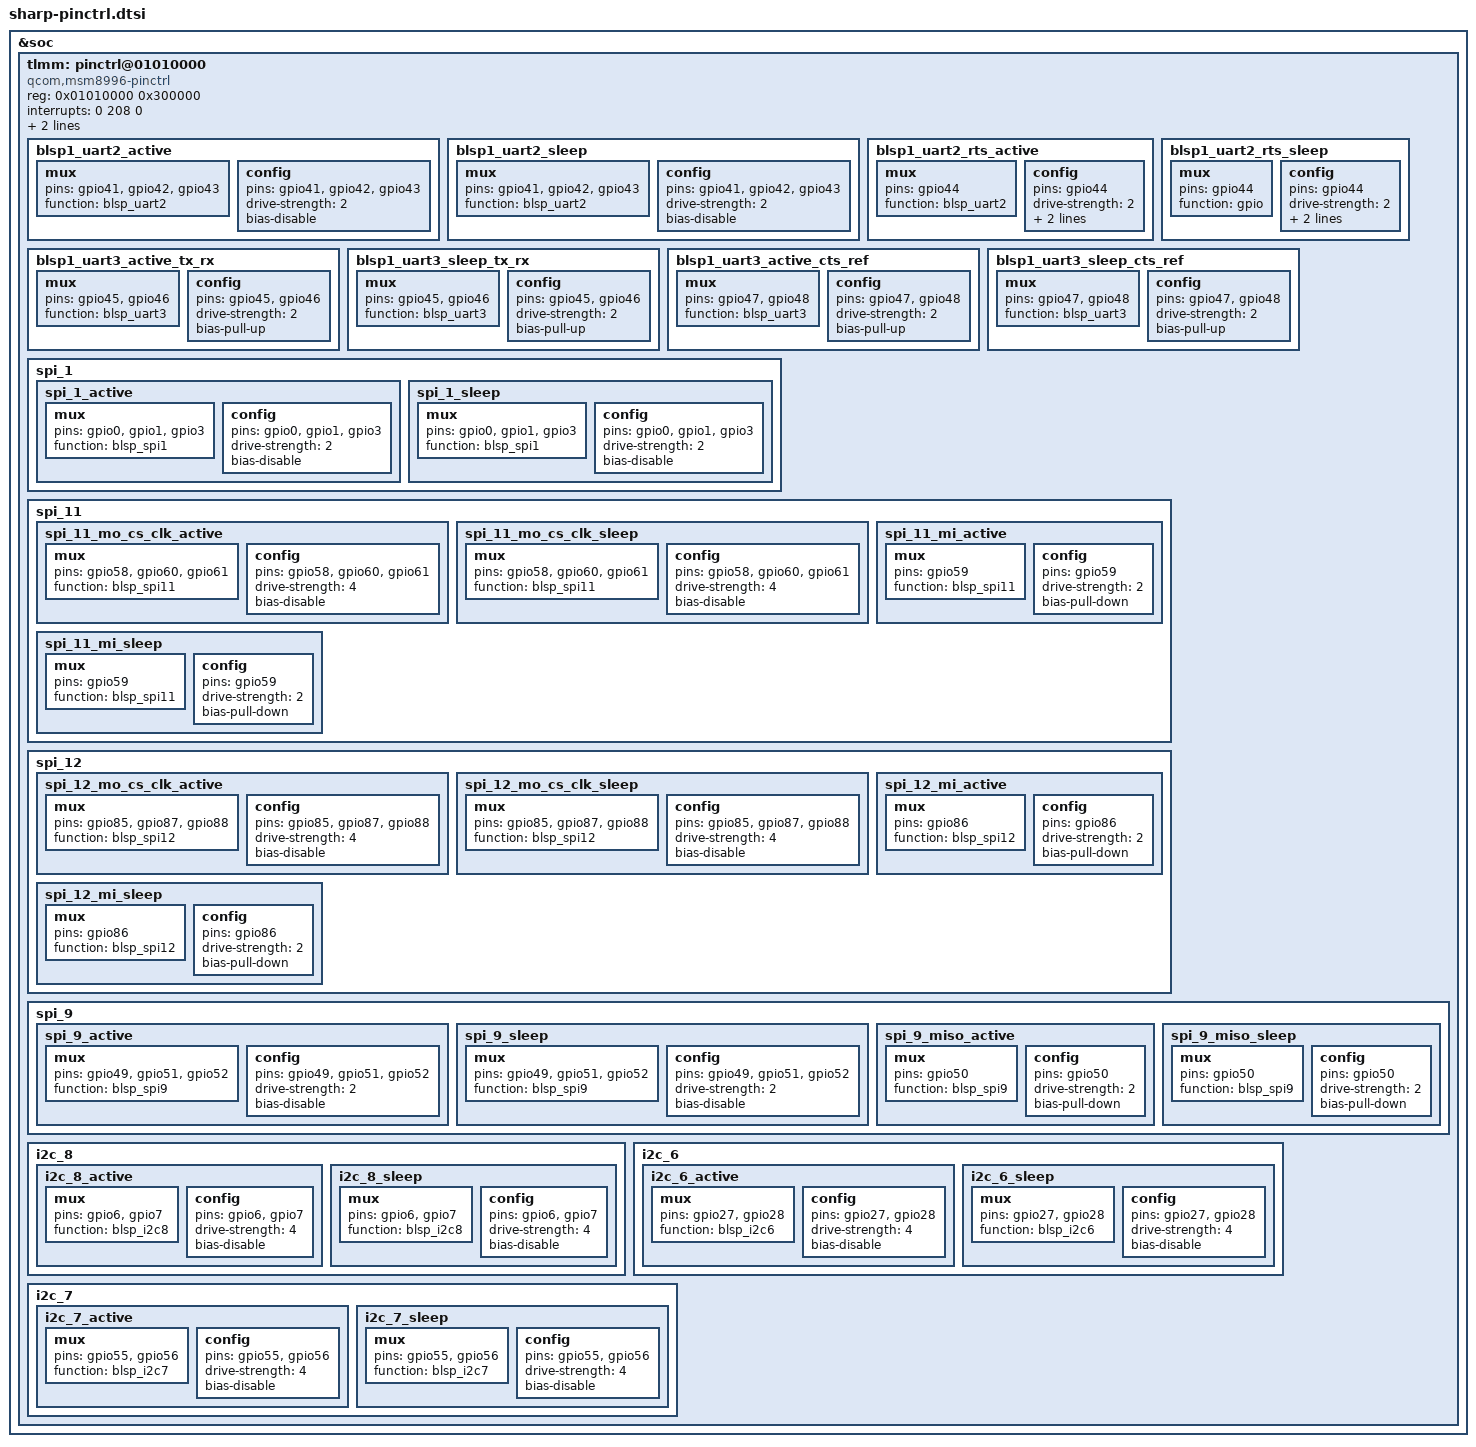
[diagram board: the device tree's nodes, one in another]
/* Copyright (c) 2014-2015, The Linux Foundation. All rights reserved.
 *
 * This program is free software; you can redistribute it and/or modify
 * it under the terms of the GNU General Public License version 2 and
 * only version 2 as published by the Free Software Foundation.
 *
 * This program is distributed in the hope that it will be useful,
 * but WITHOUT ANY WARRANTY; without even the implied warranty of
 * MERCHANTABILITY or FITNESS FOR A PARTICULAR PURPOSE.  See the
 * GNU General Public License for more details.
 */

&soc {
	tlmm: pinctrl@01010000 {
		compatible = "qcom,msm8996-pinctrl";
		reg = <0x01010000 0x300000>;
		interrupts = <0 208 0>;
		gpio-controller;
		#gpio-cells = <2>;
		interrupt-controller;
		#interrupt-cells = <2>;

		/*****************************************/
		/*	UART/Serial							 */
		/*****************************************/
		blsp1_uart2_active: blsp1_uart2_active {
			mux {
// Bluetooth Driver Mod-S
//				pins = "gpio41", "gpio42", "gpio43", "gpio44";
				pins = "gpio41", "gpio42", "gpio43";
// Bluetooth Driver Mod-E
				function = "blsp_uart2";
			};

			config {
// Bluetooth Driver Mod-S
//				pins = "gpio41", "gpio42", "gpio43", "gpio44";
				pins = "gpio41", "gpio42", "gpio43";
// Bluetooth Driver Mod-E
				drive-strength = <2>;
				bias-disable;
			};
		};

		blsp1_uart2_sleep: blsp1_uart2_sleep {
			mux {
// Bluetooth Driver Mod-S
//				pins = "gpio41", "gpio42", "gpio43", "gpio44";
				pins = "gpio41", "gpio42", "gpio43";
// Bluetooth Driver Mod-E
				function = "blsp_uart2";
			};

			config {
// Bluetooth Driver Mod-S
//				pins = "gpio41", "gpio42", "gpio43", "gpio44";
				pins = "gpio41", "gpio42", "gpio43";
// Bluetooth Driver Mod-E
				drive-strength = <2>;
				bias-disable;
			};
		};

// Bluetooth Driver Add-S
		blsp1_uart2_rts_active: blsp1_uart2_rts_active {
			mux {
				pins = "gpio44";
				function = "blsp_uart2";
			};

			config {
				pins = "gpio44";
				drive-strength = <2>;
				output-low;
				bias-disable;
			};
		};

		blsp1_uart2_rts_sleep: blsp1_uart2_rts_sleep {
			mux {
				pins = "gpio44";
				function = "gpio";
			};

			config {
				pins = "gpio44";
				drive-strength = <2>;
				output-high;
				bias-disable;
			};
		};
// Bluetooth Driver Add-E

		blsp1_uart3_active_tx_rx: blsp1_uart3_active_tx_rx {
			mux {
				pins = "gpio45", "gpio46";
				function = "blsp_uart3";
			};

			config {
				pins = "gpio45", "gpio46";
				drive-strength = <2>;
				bias-pull-up;
			};
		};

		blsp1_uart3_sleep_tx_rx: blsp1_uart3_sleep_tx_rx {
			mux {
				pins = "gpio45", "gpio46";
				function = "blsp_uart3";
			};

			config {
				pins = "gpio45", "gpio46";
				drive-strength = <2>;
				bias-pull-up;
			};
		};

		blsp1_uart3_active_cts_ref: blsp1_uart3_active_cts_ref {
			mux {
				pins = "gpio47", "gpio48";
				function = "blsp_uart3";
			};

			config {
				pins = "gpio47", "gpio48";
				drive-strength = <2>;
				bias-pull-up;
			};
		};

		blsp1_uart3_sleep_cts_ref: blsp1_uart3_sleep_cts_ref {
			mux {
				pins = "gpio47", "gpio48";
				function = "blsp_uart3";
			};

			config {
				pins = "gpio47", "gpio48";
				drive-strength = <2>;
				bias-pull-up;
			};
		};


		/*****************************************/
		/*	SPI									 */
		/*****************************************/
		spi_1 {
			spi_1_active: spi_1_active {
				mux {
					pins = "gpio0", "gpio1", "gpio3";
					function = "blsp_spi1";
				};

				config {
					pins = "gpio0", "gpio1", "gpio3";
					drive-strength = <2>;
					bias-disable;
				};
			};

			spi_1_sleep: spi_1_sleep {
				mux {
					pins = "gpio0", "gpio1", "gpio3";
					function = "blsp_spi1";
				};

				config {
					pins = "gpio0", "gpio1", "gpio3";
					drive-strength = <2>;
					bias-disable;
				};
			};
		};

		spi_11 {
			spi_11_mo_cs_clk_active: spi_11_mo_cs_clk_active {
				mux {
					pins = "gpio58", "gpio60", "gpio61";
					function = "blsp_spi11";
				};

				config {
					pins = "gpio58", "gpio60", "gpio61";
					drive-strength = <4>;
					bias-disable;
				};
			};

			spi_11_mo_cs_clk_sleep: spi_11_mo_cs_clk_sleep {
				mux {
					pins = "gpio58", "gpio60", "gpio61";
					function = "blsp_spi11";
				};

				config {
					pins = "gpio58", "gpio60", "gpio61";
					drive-strength = <4>;
					bias-disable;
				};
			};

			spi_11_mi_active: spi_11_mi_active {
				mux {
					pins = "gpio59";
					function = "blsp_spi11";
				};

				config {
					pins = "gpio59";
					drive-strength = <2>;
					bias-pull-down;
				};
			};

			spi_11_mi_sleep: spi_11_mi_sleep {
				mux {
					pins = "gpio59";
					function = "blsp_spi11";
				};

				config {
					pins = "gpio59";
					drive-strength = <2>;
					bias-pull-down;
				};
			};
		};

		spi_12 {
			spi_12_mo_cs_clk_active: spi_12_mo_cs_clk_active {
				mux {
					pins = "gpio85", "gpio87", "gpio88";
					function = "blsp_spi12";
				};

				config {
					pins = "gpio85", "gpio87", "gpio88";
					drive-strength = <4>;
					bias-disable;
				};
			};

			spi_12_mo_cs_clk_sleep: spi_12_mo_cs_clk_sleep {
				mux {
					pins = "gpio85", "gpio87", "gpio88";
					function = "blsp_spi12";
				};

				config {
					pins = "gpio85", "gpio87", "gpio88";
					drive-strength = <4>;
					bias-disable;
				};
			};

			spi_12_mi_active: spi_12_mi_active {
				mux {
					pins = "gpio86";
					function = "blsp_spi12";
				};

				config {
					pins = "gpio86";
					drive-strength = <2>;
					bias-pull-down;
				};
			};

			spi_12_mi_sleep: spi_12_mi_sleep {
				mux {
					pins = "gpio86";
					function = "blsp_spi12";
				};

				config {
					pins = "gpio86";
					drive-strength = <2>;
					bias-pull-down;
				};
			};
		};

		spi_9 {
			spi_9_active: spi_9_active {
				mux {
					pins = "gpio49", "gpio51", "gpio52";
					function = "blsp_spi9";
				};

				config {
					pins = "gpio49", "gpio51", "gpio52";
					drive-strength = <2>;
					bias-disable;
				};
			};

			spi_9_sleep: spi_9_sleep {
				mux {
					pins = "gpio49", "gpio51", "gpio52";
					function = "blsp_spi9";
				};

				config {
					pins = "gpio49", "gpio51", "gpio52";
					drive-strength = <2>;
					bias-disable;
				};
			};

			spi_9_miso_active: spi_9_miso_active {
				mux {
					pins = "gpio50";
					function = "blsp_spi9";
				};

				config {
					pins = "gpio50";
					drive-strength = <2>;
					bias-pull-down;
				};
			};

			spi_9_miso_sleep: spi_9_miso_sleep {
				mux {
					pins = "gpio50";
					function = "blsp_spi9";
				};

				config {
					pins = "gpio50";
					drive-strength = <2>;
					bias-pull-down;
				};
			};

		};

		/*****************************************/
		/*	I2C									 */
		/*****************************************/
		i2c_8 {
			i2c_8_active: i2c_8_active {
				mux {
					pins = "gpio6", "gpio7";
					function = "blsp_i2c8";
				};

				config {
					pins = "gpio6", "gpio7";
					drive-strength = <4>;
					bias-disable;
				};
			};

			i2c_8_sleep: i2c_8_sleep {
				mux {
					pins = "gpio6", "gpio7";
					function = "blsp_i2c8";
				};

				config {
					pins = "gpio6", "gpio7";
					drive-strength = <4>;
					/delete-property/ bias-pull-up;
					bias-disable;
				};
			};
		};

		i2c_6 {
			i2c_6_active: i2c_6_active {
				mux {
					pins = "gpio27", "gpio28";
					function = "blsp_i2c6";
				};

				config {
					pins = "gpio27", "gpio28";
					drive-strength = <4>;
					bias-disable;
				};
			};

			i2c_6_sleep: i2c_6_sleep {
				mux {
					pins = "gpio27", "gpio28";
					function = "blsp_i2c6";
				};

				config {
					pins = "gpio27", "gpio28";
					drive-strength = <4>;
					/delete-property/ bias-pull-up;
					/delete-property/ bias-pull-down;
					bias-disable;
				};
			};
		};

		i2c_7 {
			i2c_7_active: i2c_7_active {
				mux {
					pins = "gpio55", "gpio56";
					function = "blsp_i2c7";
				};

				config {
					pins = "gpio55", "gpio56";
					drive-strength = <4>;
					bias-disable;
				};
			};

			i2c_7_sleep: i2c_7_sleep {
				mux {
					pins = "gpio55", "gpio56";
					function = "blsp_i2c7";
				};

				config {
					pins = "gpio55", "gpio56";
					drive-strength = <4>;
					/delete-property/ bias-pull-up;
					bias-disable;
				};
			};
		};
	};
};
